# EnumComboWidth register map
File version: 1.0
Test the SFD combo field width limit
CPU: CM4 r0p0, little endian, no FPU, 4 interrupt priority bits, 16 interrupts
Registers are 32-bit, read-only, reset 0x0 unless marked. A register's access mark holds for its fields unless they carry their own. Offsets are from the block's base; lines under a group give offsets from that group; [hi:lo] are bit positions; {n}, {i} and the like mark numbered series; 'fields as' and 'values as' point back to an identical list; <NAME> marks a mode.

## Memory map
0x40000000 TEST size 0x4 — Test peripheral

## TEST — Test peripheral
Base 0x40000000
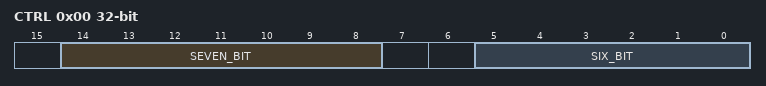
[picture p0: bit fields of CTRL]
0x00 CTRL — Test control register
  [14:8] SEVEN_BIT
    9=NINE (Value nine)
  [5:0] SIX_BIT
    1=ONE (Value one)
